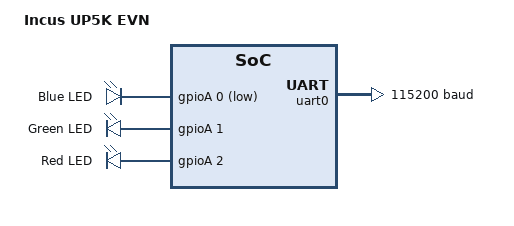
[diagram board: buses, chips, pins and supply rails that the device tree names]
/*
 * Copyright (c) 2018 Limacon Audio Limited
 *
 * SPDX-License-Identifier: Apache-2.0
 */

/dts-v1/;

#include <vexriscv_incus_soc.dtsi>

/ {
	model = "Incus UP5K EVN";
	compatible = "spinal,incus";

	aliases {
		led0 = &led0;
		led1 = &led1;
		led2 = &led2;
	};

	chosen {
		zephyr,console = &uart0;
		zephyr,shell-uart = &uart0;
	};

	leds {
		compatible = "gpio-leds";
		led0: led_0 {
			gpios = <&gpioA 0 GPIO_INT_ACTIVE_LOW>;
			label = "Blue LED";
		};
		led1: led_1 {
			gpios = <&gpioA 1 GPIO_INT_ACTIVE_HIGH>;
			label = "Green LED";
		};
		led2: led_2 {
			gpios = <&gpioA 2 GPIO_INT_ACTIVE_HIGH>;
			label = "Red LED";
		};
	};
};

&gpioA {
	status = "ok";
};


&uart0 {
	status = "ok";
	current-speed = <115200>;
	clock-frequency = <12000000>;
};
